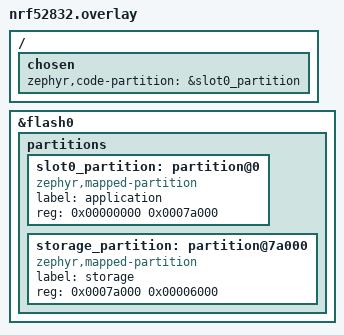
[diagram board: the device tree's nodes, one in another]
/ {
	chosen {
		zephyr,code-partition = &slot0_partition;
	};
};

&flash0 {
	/delete-node/ partitions;

	partitions {
		ranges;
		#address-cells = <1>;
		#size-cells = <1>;

		slot0_partition: partition@0 {
			compatible = "zephyr,mapped-partition";
			label = "application";
			reg = <0x00000000 0x0007a000>;
		};

		storage_partition: partition@7a000 {
			compatible = "zephyr,mapped-partition";
			label = "storage";
			reg = <0x0007a000 0x00006000>;
		};
	};
};
